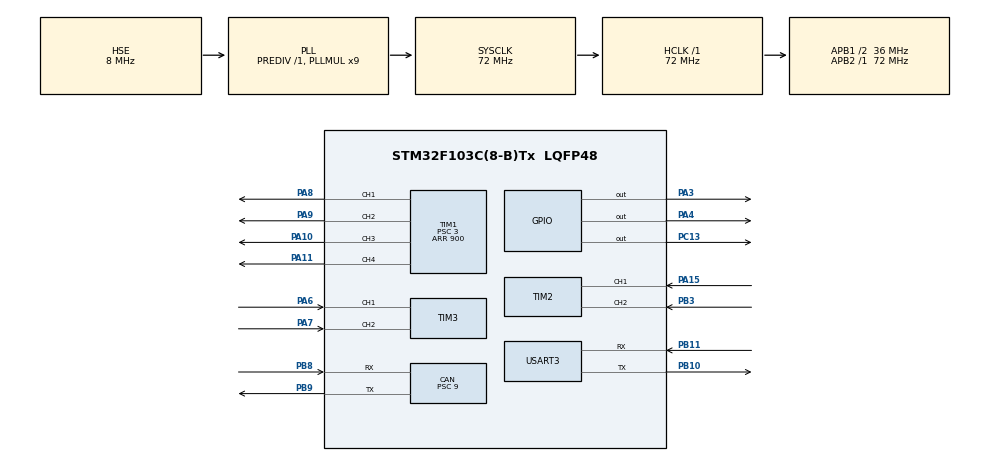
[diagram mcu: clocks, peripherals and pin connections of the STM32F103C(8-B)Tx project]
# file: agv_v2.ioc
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CAN.BS1=CAN_BS1_10TQ
CAN.BS2=CAN_BS2_5TQ
CAN.CalculateBaudRate=250000
CAN.CalculateTimeBit=4000
CAN.CalculateTimeQuantum=250.0
CAN.Prescaler=9
Mcu.Family=STM32F1
Mcu.Name=STM32F103C(8-B)Tx
Mcu.Package=LQFP48
NVIC.CAN1_SCE_IRQn=true\:0\:0\:false\:false\:true\:true\:true
NVIC.PriorityGroup=NVIC_PRIORITYGROUP_4
NVIC.TIM2_IRQn=true\:0\:0\:false\:false\:true\:true\:true
NVIC.TIM3_IRQn=true\:0\:0\:false\:false\:true\:true\:true
NVIC.USB_LP_CAN1_RX0_IRQn=true\:0\:0\:false\:false\:true\:true\:true
PA10.Signal=S_TIM1_CH3
PA11.Signal=S_TIM1_CH4
PA13.Mode=Serial_Wire
PA13.Signal=SYS_JTMS-SWDIO
PA14.Mode=Serial_Wire
PA14.Signal=SYS_JTCK-SWCLK
PA15.GPIO_PuPd=GPIO_PULLUP
PA15.Signal=S_TIM2_CH1_ETR
PA3.Signal=GPIO_Output
PA4.Signal=GPIO_Output
PA6.GPIO_PuPd=GPIO_PULLUP
PA6.Signal=S_TIM3_CH1
PA7.GPIO_PuPd=GPIO_PULLUP
PA7.Signal=S_TIM3_CH2
PA8.Signal=S_TIM1_CH1
PA9.Signal=S_TIM1_CH2
PB10.Mode=Asynchronous
PB10.Signal=USART3_TX
PB11.Mode=Asynchronous
PB11.Signal=USART3_RX
PB3.GPIO_PuPd=GPIO_PULLUP
PB3.Signal=S_TIM2_CH2
PB8.GPIO_PuPd=GPIO_NOPULL
PB8.Mode=CAN_Activate
PB8.Signal=CAN_RX
PB9.Mode=CAN_Activate
PB9.Signal=CAN_TX
PC13-TAMPER-RTC.Signal=GPIO_Output
PD0-OSC_IN.Mode=HSE-External-Oscillator
PD0-OSC_IN.Signal=RCC_OSC_IN
PD1-OSC_OUT.Mode=HSE-External-Oscillator
PD1-OSC_OUT.Signal=RCC_OSC_OUT
ProjectManager.HeapSize=0x200
ProjectManager.StackSize=0x400
ProjectManager.TargetToolchain=STM32CubeIDE
RCC.AHBFreq_Value=72000000
RCC.APB1CLKDivider=RCC_HCLK_DIV2
RCC.APB1Freq_Value=36000000
RCC.APB1TimFreq_Value=72000000
RCC.APB2Freq_Value=72000000
RCC.APB2TimFreq_Value=72000000
RCC.HCLKFreq_Value=72000000
RCC.PLLMUL=RCC_PLL_MUL9
RCC.PLLSourceVirtual=RCC_PLLSOURCE_HSE
RCC.SYSCLKFreq_VALUE=72000000
RCC.SYSCLKSource=RCC_SYSCLKSOURCE_PLLCLK
RCC.USBFreq_Value=72000000
SH.S_TIM1_CH1.0=TIM1_CH1,PWM Generation1 CH1
SH.S_TIM1_CH2.0=TIM1_CH2,PWM Generation2 CH2
SH.S_TIM1_CH3.0=TIM1_CH3,PWM Generation3 CH3
SH.S_TIM1_CH4.0=TIM1_CH4,PWM Generation4 CH4
SH.S_TIM2_CH1_ETR.0=TIM2_CH1,Encoder_Interface
SH.S_TIM2_CH2.0=TIM2_CH2,Encoder_Interface
SH.S_TIM3_CH1.0=TIM3_CH1,Encoder_Interface
SH.S_TIM3_CH2.0=TIM3_CH2,Encoder_Interface
TIM1.Channel-PWM\ Generation1\ CH1=TIM_CHANNEL_1
TIM1.Channel-PWM\ Generation2\ CH2=TIM_CHANNEL_2
TIM1.Channel-PWM\ Generation3\ CH3=TIM_CHANNEL_3
TIM1.Channel-PWM\ Generation4\ CH4=TIM_CHANNEL_4
TIM1.Period=900
TIM1.Prescaler=3
TIM2.AutoReloadPreload=TIM_AUTORELOAD_PRELOAD_ENABLE
TIM2.EncoderMode=TIM_ENCODERMODE_TI12
TIM2.IC1Filter=10
TIM2.IC2Filter=10
TIM3.AutoReloadPreload=TIM_AUTORELOAD_PRELOAD_ENABLE
TIM3.EncoderMode=TIM_ENCODERMODE_TI12
TIM3.IC1Filter=10
TIM3.IC2Filter=10
USART3.VirtualMode=VM_ASYNC
VP_TIM1_VS_ClockSourceINT.Mode=Internal
board=custom

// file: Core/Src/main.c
/* USER CODE BEGIN Header */
/**
  ******************************************************************************
  * @file           : main.c
  * @brief          : Main program body
  ******************************************************************************
  * @attention
  *
  * Copyright (c) 2023 STMicroelectronics.
  * All rights reserved.
  *
  * This software is licensed under terms that can be found in the LICENSE file
  * in the root directory of this software component.
  * If no LICENSE file comes with this software, it is provided AS-IS.
  *
  ******************************************************************************
  */
/* USER CODE END Header */
#include "main.h"

/* USER CODE BEGIN Includes */
#include "gz_can.h"
#include "motor.h"
/* USER CODE END Includes */

CAN_HandleTypeDef hcan;

TIM_HandleTypeDef htim1;
TIM_HandleTypeDef htim2;
TIM_HandleTypeDef htim3;

UART_HandleTypeDef huart3;

/* USER CODE BEGIN PV */
double m1speed=0.00, m2speed=0.00;
float left, right, s1=3.14;
char ss[4];
/* USER CODE END PV */

void SystemClock_Config(void);
static void MX_GPIO_Init(void);
static void MX_TIM1_Init(void);
static void MX_TIM2_Init(void);
static void MX_TIM3_Init(void);
static void MX_CAN_Init(void);
static void MX_USART3_UART_Init(void);

int main(void)
{

  /* MCU Configuration--------------------------------------------------------*/

  /* Reset of all peripherals, Initializes the Flash interface and the Systick. */
  HAL_Init();

  /* Configure the system clock */
  SystemClock_Config();

  /* Initialize all configured peripherals */
  MX_GPIO_Init();
  MX_TIM1_Init();
  MX_TIM2_Init();
  MX_TIM3_Init();
  MX_CAN_Init();
  MX_USART3_UART_Init();
  /* USER CODE BEGIN 2 */
  HAL_GPIO_WritePin(GPIOC, GPIO_PIN_13, ENABLE);
  motor_Init();
  GZ_CAN_Init();
  struct MOTOR motor;
  motor.current=10;
  /* USER CODE END 2 */

  /* Infinite loop */
  /* USER CODE BEGIN WHILE */
  while (1)
  {
	  memcpy(ss,&s1,4);
	  GZ_CAN_Receive_motor1(&left,&right);
	  //test1= 0.3;
	  //test2 = 0.3;
	  //GZ_CAN_Receive_motor2(&m2speed);
	  //motor1_set_speed(450);
	  //motor2_set_speed(450);
	 encoder_loop((double)left,(double)right);
    /* USER CODE END WHILE */

  }
}

void SystemClock_Config(void)
{
  RCC_OscInitTypeDef RCC_OscInitStruct = {0};
  RCC_ClkInitTypeDef RCC_ClkInitStruct = {0};

  /** Initializes the RCC Oscillators according to the specified parameters
  * in the RCC_OscInitTypeDef structure.
  */
  RCC_OscInitStruct.OscillatorType = RCC_OSCILLATORTYPE_HSE;
  RCC_OscInitStruct.HSEState = RCC_HSE_ON;
  RCC_OscInitStruct.HSEPredivValue = RCC_HSE_PREDIV_DIV1;
  RCC_OscInitStruct.HSIState = RCC_HSI_ON;
  RCC_OscInitStruct.PLL.PLLState = RCC_PLL_ON;
  RCC_OscInitStruct.PLL.PLLSource = RCC_PLLSOURCE_HSE;
  RCC_OscInitStruct.PLL.PLLMUL = RCC_PLL_MUL9;
  if (HAL_RCC_OscConfig(&RCC_OscInitStruct) != HAL_OK)
  {
    Error_Handler();
  }
  /** Initializes the CPU, AHB and APB buses clocks
  */
  RCC_ClkInitStruct.ClockType = RCC_CLOCKTYPE_HCLK|RCC_CLOCKTYPE_SYSCLK
                              |RCC_CLOCKTYPE_PCLK1|RCC_CLOCKTYPE_PCLK2;
  RCC_ClkInitStruct.SYSCLKSource = RCC_SYSCLKSOURCE_PLLCLK;
  RCC_ClkInitStruct.AHBCLKDivider = RCC_SYSCLK_DIV1;
  RCC_ClkInitStruct.APB1CLKDivider = RCC_HCLK_DIV2;
  RCC_ClkInitStruct.APB2CLKDivider = RCC_HCLK_DIV1;

  if (HAL_RCC_ClockConfig(&RCC_ClkInitStruct, FLASH_LATENCY_2) != HAL_OK)
  {
    Error_Handler();
  }
}

static void MX_CAN_Init(void)
{

  hcan.Instance = CAN1;
  hcan.Init.Prescaler = 9;
  hcan.Init.Mode = CAN_MODE_NORMAL;
  hcan.Init.SyncJumpWidth = CAN_SJW_1TQ;
  hcan.Init.TimeSeg1 = CAN_BS1_10TQ;
  hcan.Init.TimeSeg2 = CAN_BS2_5TQ;
  hcan.Init.TimeTriggeredMode = DISABLE;
  hcan.Init.AutoBusOff = DISABLE;
  hcan.Init.AutoWakeUp = DISABLE;
  hcan.Init.AutoRetransmission = DISABLE;
  hcan.Init.ReceiveFifoLocked = DISABLE;
  hcan.Init.TransmitFifoPriority = DISABLE;
  if (HAL_CAN_Init(&hcan) != HAL_OK)
  {
    Error_Handler();
  }

}

static void MX_TIM1_Init(void)
{

  TIM_ClockConfigTypeDef sClockSourceConfig = {0};
  TIM_MasterConfigTypeDef sMasterConfig = {0};
  TIM_OC_InitTypeDef sConfigOC = {0};
  TIM_BreakDeadTimeConfigTypeDef sBreakDeadTimeConfig = {0};

  htim1.Instance = TIM1;
  htim1.Init.Prescaler = 3;
  htim1.Init.CounterMode = TIM_COUNTERMODE_UP;
  htim1.Init.Period = 900;
  htim1.Init.ClockDivision = TIM_CLOCKDIVISION_DIV1;
  htim1.Init.RepetitionCounter = 0;
  htim1.Init.AutoReloadPreload = TIM_AUTORELOAD_PRELOAD_DISABLE;
  if (HAL_TIM_Base_Init(&htim1) != HAL_OK)
  {
    Error_Handler();
  }
  sClockSourceConfig.ClockSource = TIM_CLOCKSOURCE_INTERNAL;
  if (HAL_TIM_ConfigClockSource(&htim1, &sClockSourceConfig) != HAL_OK)
  {
    Error_Handler();
  }
  if (HAL_TIM_PWM_Init(&htim1) != HAL_OK)
  {
    Error_Handler();
  }
  sMasterConfig.MasterOutputTrigger = TIM_TRGO_RESET;
  sMasterConfig.MasterSlaveMode = TIM_MASTERSLAVEMODE_DISABLE;
  if (HAL_TIMEx_MasterConfigSynchronization(&htim1, &sMasterConfig) != HAL_OK)
  {
    Error_Handler();
  }
  sConfigOC.OCMode = TIM_OCMODE_PWM1;
  sConfigOC.Pulse = 0;
  sConfigOC.OCPolarity = TIM_OCPOLARITY_HIGH;
  sConfigOC.OCNPolarity = TIM_OCNPOLARITY_HIGH;
  sConfigOC.OCFastMode = TIM_OCFAST_DISABLE;
  sConfigOC.OCIdleState = TIM_OCIDLESTATE_RESET;
  sConfigOC.OCNIdleState = TIM_OCNIDLESTATE_RESET;
  if (HAL_TIM_PWM_ConfigChannel(&htim1, &sConfigOC, TIM_CHANNEL_1) != HAL_OK)
  {
    Error_Handler();
  }
  if (HAL_TIM_PWM_ConfigChannel(&htim1, &sConfigOC, TIM_CHANNEL_2) != HAL_OK)
  {
    Error_Handler();
  }
  if (HAL_TIM_PWM_ConfigChannel(&htim1, &sConfigOC, TIM_CHANNEL_3) != HAL_OK)
  {
    Error_Handler();
  }
  if (HAL_TIM_PWM_ConfigChannel(&htim1, &sConfigOC, TIM_CHANNEL_4) != HAL_OK)
  {
    Error_Handler();
  }
  sBreakDeadTimeConfig.OffStateRunMode = TIM_OSSR_DISABLE;
  sBreakDeadTimeConfig.OffStateIDLEMode = TIM_OSSI_DISABLE;
  sBreakDeadTimeConfig.LockLevel = TIM_LOCKLEVEL_OFF;
  sBreakDeadTimeConfig.DeadTime = 0;
  sBreakDeadTimeConfig.BreakState = TIM_BREAK_DISABLE;
  sBreakDeadTimeConfig.BreakPolarity = TIM_BREAKPOLARITY_HIGH;
  sBreakDeadTimeConfig.AutomaticOutput = TIM_AUTOMATICOUTPUT_DISABLE;
  if (HAL_TIMEx_ConfigBreakDeadTime(&htim1, &sBreakDeadTimeConfig) != HAL_OK)
  {
    Error_Handler();
  }
  HAL_TIM_MspPostInit(&htim1);

}

static void MX_TIM2_Init(void)
{

  TIM_Encoder_InitTypeDef sConfig = {0};
  TIM_MasterConfigTypeDef sMasterConfig = {0};

  htim2.Instance = TIM2;
  htim2.Init.Prescaler = 0;
  htim2.Init.CounterMode = TIM_COUNTERMODE_UP;
  htim2.Init.Period = 65535;
  htim2.Init.ClockDivision = TIM_CLOCKDIVISION_DIV1;
  htim2.Init.AutoReloadPreload = TIM_AUTORELOAD_PRELOAD_ENABLE;
  sConfig.EncoderMode = TIM_ENCODERMODE_TI12;
  sConfig.IC1Polarity = TIM_ICPOLARITY_RISING;
  sConfig.IC1Selection = TIM_ICSELECTION_DIRECTTI;
  sConfig.IC1Prescaler = TIM_ICPSC_DIV1;
  sConfig.IC1Filter = 10;
  sConfig.IC2Polarity = TIM_ICPOLARITY_RISING;
  sConfig.IC2Selection = TIM_ICSELECTION_DIRECTTI;
  sConfig.IC2Prescaler = TIM_ICPSC_DIV1;
  sConfig.IC2Filter = 10;
  if (HAL_TIM_Encoder_Init(&htim2, &sConfig) != HAL_OK)
  {
    Error_Handler();
  }
  sMasterConfig.MasterOutputTrigger = TIM_TRGO_RESET;
  sMasterConfig.MasterSlaveMode = TIM_MASTERSLAVEMODE_DISABLE;
  if (HAL_TIMEx_MasterConfigSynchronization(&htim2, &sMasterConfig) != HAL_OK)
  {
    Error_Handler();
  }

}

static void MX_TIM3_Init(void)
{

  TIM_Encoder_InitTypeDef sConfig = {0};
  TIM_MasterConfigTypeDef sMasterConfig = {0};

  htim3.Instance = TIM3;
  htim3.Init.Prescaler = 0;
  htim3.Init.CounterMode = TIM_COUNTERMODE_UP;
  htim3.Init.Period = 65535;
  htim3.Init.ClockDivision = TIM_CLOCKDIVISION_DIV1;
  htim3.Init.AutoReloadPreload = TIM_AUTORELOAD_PRELOAD_ENABLE;
  sConfig.EncoderMode = TIM_ENCODERMODE_TI12;
  sConfig.IC1Polarity = TIM_ICPOLARITY_RISING;
  sConfig.IC1Selection = TIM_ICSELECTION_DIRECTTI;
  sConfig.IC1Prescaler = TIM_ICPSC_DIV1;
  sConfig.IC1Filter = 10;
  sConfig.IC2Polarity = TIM_ICPOLARITY_RISING;
  sConfig.IC2Selection = TIM_ICSELECTION_DIRECTTI;
  sConfig.IC2Prescaler = TIM_ICPSC_DIV1;
  sConfig.IC2Filter = 10;
  if (HAL_TIM_Encoder_Init(&htim3, &sConfig) != HAL_OK)
  {
    Error_Handler();
  }
  sMasterConfig.MasterOutputTrigger = TIM_TRGO_RESET;
  sMasterConfig.MasterSlaveMode = TIM_MASTERSLAVEMODE_DISABLE;
  if (HAL_TIMEx_MasterConfigSynchronization(&htim3, &sMasterConfig) != HAL_OK)
  {
    Error_Handler();
  }

}

static void MX_USART3_UART_Init(void)
{

  huart3.Instance = USART3;
  huart3.Init.BaudRate = 115200;
  huart3.Init.WordLength = UART_WORDLENGTH_8B;
  huart3.Init.StopBits = UART_STOPBITS_1;
  huart3.Init.Parity = UART_PARITY_NONE;
  huart3.Init.Mode = UART_MODE_TX_RX;
  huart3.Init.HwFlowCtl = UART_HWCONTROL_NONE;
  huart3.Init.OverSampling = UART_OVERSAMPLING_16;
  if (HAL_UART_Init(&huart3) != HAL_OK)
  {
    Error_Handler();
  }

}

static void MX_GPIO_Init(void)
{
  GPIO_InitTypeDef GPIO_InitStruct = {0};

  /* GPIO Ports Clock Enable */
  __HAL_RCC_GPIOC_CLK_ENABLE();
  __HAL_RCC_GPIOD_CLK_ENABLE();
  __HAL_RCC_GPIOA_CLK_ENABLE();
  __HAL_RCC_GPIOB_CLK_ENABLE();

  /*Configure GPIO pin Output Level */
  HAL_GPIO_WritePin(GPIOC, GPIO_PIN_13, GPIO_PIN_RESET);

  /*Configure GPIO pin Output Level */
  HAL_GPIO_WritePin(GPIOA, GPIO_PIN_3|GPIO_PIN_4, GPIO_PIN_RESET);

  /*Configure GPIO pin : PC13 */
  GPIO_InitStruct.Pin = GPIO_PIN_13;
  GPIO_InitStruct.Mode = GPIO_MODE_OUTPUT_PP;
  GPIO_InitStruct.Pull = GPIO_NOPULL;
  GPIO_InitStruct.Speed = GPIO_SPEED_FREQ_LOW;
  HAL_GPIO_Init(GPIOC, &GPIO_InitStruct);

  /*Configure GPIO pins : PA3 PA4 */
  GPIO_InitStruct.Pin = GPIO_PIN_3|GPIO_PIN_4;
  GPIO_InitStruct.Mode = GPIO_MODE_OUTPUT_PP;
  GPIO_InitStruct.Pull = GPIO_NOPULL;
  GPIO_InitStruct.Speed = GPIO_SPEED_FREQ_LOW;
  HAL_GPIO_Init(GPIOA, &GPIO_InitStruct);

}

void Error_Handler(void)
{
  __disable_irq();
  while (1)
  {
  }
}
